AUTOSAR XML (schema 00047)
package /SWUC
  process design amsr_swupdateclient_process_design: executable=amsr_swupdateclient
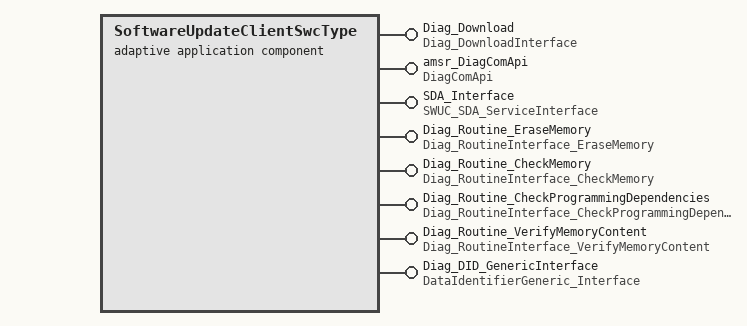
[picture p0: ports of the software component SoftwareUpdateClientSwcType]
  adaptive application sw component type SoftwareUpdateClientSwcType
    4 x provide/require port:
      DiagCore_KeyValueStorage: provided-required-interface=PersistencyInterface_DiagCore_KeyValueStorage
      TPUM_SwPackage_KeyValueStorage: provided-required-interface=PersistencyInterface_TPUM_SwPackage_KeyValueStorage
      TPUM_SwCluster_KeyValueStorage: provided-required-interface=PersistencyInterface_TPUM_SwCluster_KeyValueStorage
      TPUM_FileStorage: provided-required-interface=PersistencyInterface_TPUM_FileStorage
    8 x provide port:
      Diag_Download: provided-interface=Diag_DownloadInterface
      amsr_DiagComApi: provided-interface=DiagComApi
      SDA_Interface: provided-interface=SWUC_SDA_ServiceInterface
      Diag_Routine_EraseMemory: provided-interface=Diag_RoutineInterface_EraseMemory
      Diag_Routine_CheckMemory: provided-interface=Diag_RoutineInterface_CheckMemory
      Diag_Routine_CheckProgrammingDependencies: provided-interface=Diag_RoutineInterface_CheckProgrammingDependencies
      Diag_Routine_VerifyMemoryContent: provided-interface=Diag_RoutineInterface_VerifyMemoryContent
      Diag_DID_GenericInterface: provided-interface=DataIdentifierGeneric_Interface
    adaptive swc internal behavior AdaptiveSwcInternalBehavior
      6 x swc service dependency:
        SwcServiceDependency_Download: assigned-ports=role-based-port-assignment=Diag_Download
        SwcServiceDependency_EraseMemory: assigned-ports=role-based-port-assignment=Diag_Routine_EraseMemory
        SwcServiceDependency_CheckMemory: assigned-ports=role-based-port-assignment=Diag_Routine_CheckMemory
        SwcServiceDependency_CheckProgrammingDependencies: assigned-ports=role-based-port-assignment=Diag_Routine_CheckProgrammingDependencies
        SwcServiceDependency_VerifyMemoryContent: assigned-ports=role-based-port-assignment=Diag_Routine_VerifyMemoryContent
        SwcServiceDependency_DID_GenericInterface: assigned-ports=role-based-port-assignment=Diag_DID_GenericInterface
